# ATSAMV71J register map
Vendor: Microchip Technology; Series: SAMV71; File version: 0
CPU: CM7 r1p1, little endian, MPU, FPU, 3 interrupt priority bits
Registers are 32-bit, read-write, reset 0x0 unless marked. A register's access mark holds for its fields unless they carry their own. Offsets are from the block's base; [hi:lo] are bit positions.

## RSTC — Reset Controller
Base 0x400E1800; register names take the prefix RSTC_
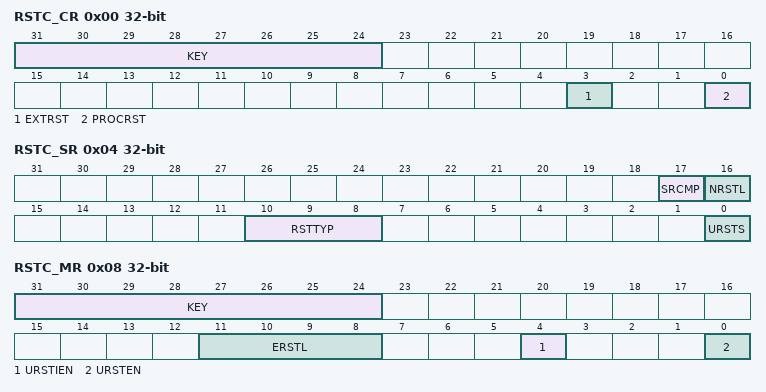
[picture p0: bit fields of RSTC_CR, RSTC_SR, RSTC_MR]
0x00 RSTC_CR wo — Control Register
  [31:24] KEY — System Reset Key
    165=PASSWD (Writing any other value in this field aborts the write operation.)
  [3] EXTRST — External Reset
  [0] PROCRST — Processor Reset
0x04 RSTC_SR ro — Status Register
  [17] SRCMP — Software Reset Command in Progress
  [16] NRSTL — NRST Pin Level
  [10:8] RSTTYP — Reset Type
    0=GENERAL_RST (First powerup reset); 1=BACKUP_RST (Return from Backup mode); 2=WDT_RST (Watchdog fault occurred); 3=SOFT_RST (Processor reset required by the software); 4=USER_RST (NRST pin detected low)
  [0] URSTS — User Reset Status
0x08 RSTC_MR — Mode Register
  [31:24] KEY — Write Access Password
    165=PASSWD (Writing any other value in this field aborts the write operation.Always reads as 0.)
  [11:8] ERSTL — External Reset Length
  [4] URSTIEN — User Reset Interrupt Enable
  [0] URSTEN — User Reset Enable

## RSWDT — Reinforced Safety Watchdog Timer
Base 0x400E1900; register names take the prefix RSWDT_
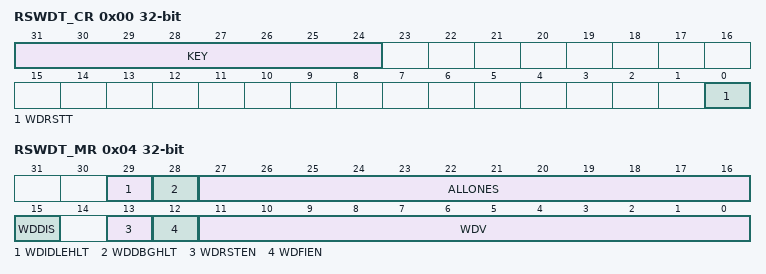
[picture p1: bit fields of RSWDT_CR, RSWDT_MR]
0x00 RSWDT_CR wo — Control Register
  [31:24] KEY — Password
    196=PASSWD (Writing any other value in this field aborts the write operation.)
  [0] WDRSTT — Watchdog Restart
0x04 RSWDT_MR — Mode Register
  [29] WDIDLEHLT — Watchdog Idle Halt
  [28] WDDBGHLT — Watchdog Debug Halt
  [27:16] ALLONES — Must Always Be Written with 0xFFF
  [15] WDDIS — Watchdog Disable
  [13] WDRSTEN — Watchdog Reset Enable
  [12] WDFIEN — Watchdog Fault Interrupt Enable
  [11:0] WDV — Watchdog Counter Value
0x08 RSWDT_SR ro — Status Register
  [0] WDUNF — Watchdog Underflow

## RTT — Real-time Timer
Base 0x400E1830; register names take the prefix RTT_
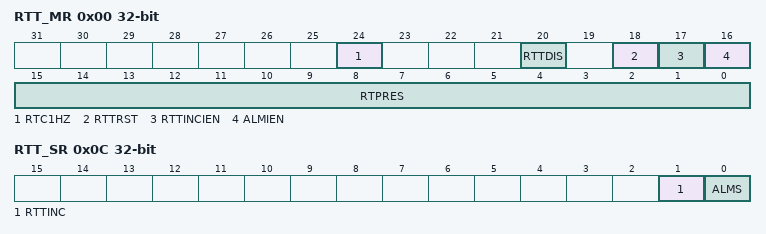
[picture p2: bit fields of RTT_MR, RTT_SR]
0x00 RTT_MR — Mode Register
  [24] RTC1HZ — Real-Time Clock 1Hz Clock Selection
  [20] RTTDIS — Real-time Timer Disable
  [18] RTTRST — Real-time Timer Restart
  [17] RTTINCIEN — Real-time Timer Increment Interrupt Enable
  [16] ALMIEN — Alarm Interrupt Enable
  [15:0] RTPRES — Real-time Timer Prescaler Value
0x04 RTT_AR — Alarm Register
  [31:0] ALMV — Alarm Value
0x08 RTT_VR ro — Value Register
  [31:0] CRTV — Current Real-time Value
0x0C RTT_SR ro — Status Register
  [1] RTTINC — Prescaler Roll-over Status (cleared on read)
  [0] ALMS — Real-time Alarm Status (cleared on read)

## TRNG — True Random Number Generator
Base 0x40070000; register names take the prefix TRNG_
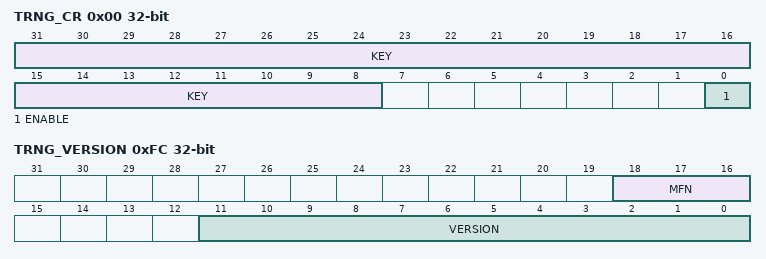
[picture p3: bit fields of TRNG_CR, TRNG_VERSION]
0x00 TRNG_CR wo — Control Register
  [31:8] KEY — Security Key
    0x524E47=PASSWD (Writing any other value in this field aborts the write operation.)
  [0] ENABLE — Enables the TRNG to Provide Random Values
0x10 TRNG_IER wo — Interrupt Enable Register
  [0] DATRDY — Data Ready Interrupt Enable
0x14 TRNG_IDR wo — Interrupt Disable Register
  [0] DATRDY — Data Ready Interrupt Disable
0x18 TRNG_IMR ro — Interrupt Mask Register
  [0] DATRDY — Data Ready Interrupt Mask
0x1C TRNG_ISR ro — Interrupt Status Register
  [0] DATRDY — Data Ready
0x50 TRNG_ODATA ro — Output Data Register
  [31:0] ODATA — Output Data
0xFC TRNG_VERSION ro — Version Register
  [18:16] MFN — Metal Fix Number
  [11:0] VERSION — Version of the Hardware Module

## UART0 — Universal Asynchronous Receiver Transmitter
Base 0x400E0800; register names take the prefix UART_
Same registers: UART1 0x400E0A00, UART2 0x400E1A00
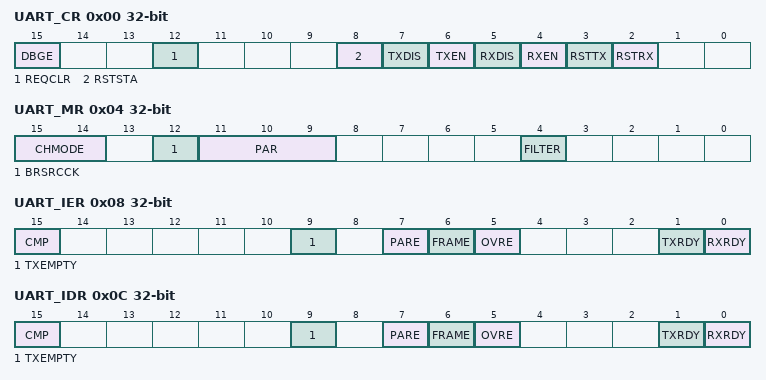
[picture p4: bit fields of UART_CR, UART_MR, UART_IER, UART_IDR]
0x00 UART_CR wo — Control Register
  [15] DBGE — Debug Enable
  [12] REQCLR — Request Clear
  [8] RSTSTA — Reset Status
  [7] TXDIS — Transmitter Disable
  [6] TXEN — Transmitter Enable
  [5] RXDIS — Receiver Disable
  [4] RXEN — Receiver Enable
  [3] RSTTX — Reset Transmitter
  [2] RSTRX — Reset Receiver
0x04 UART_MR — Mode Register
  [15:14] CHMODE — Channel Mode
    0=NORMAL (Normal mode); 1=AUTOMATIC (Automatic echo); 2=LOCAL_LOOPBACK; 3=REMOTE_LOOPBACK
  [12] BRSRCCK — Baud Rate Source Clock
    0=PERIPH_CLK (The baud rate is driven by the peripheral clock); 1=PMC_PCK (The baud rate is driven by a PMC-programmable clock PCK (see section Power Management Controller (PMC)).)
  [11:9] PAR — Parity Type
    0=EVEN (Even Parity); 1=ODD (Odd Parity); 2=SPACE (Space: parity forced to 0); 3=MARK (Mark: parity forced to 1); 4=NO (No parity)
  [4] FILTER — Receiver Digital Filter
    0=DISABLED (UART does not filter the receive line.); 1=ENABLED (UART filters the receive line using a three-sample filter (16x-bit clock) (2 over 3 majority).)
0x08 UART_IER wo — Interrupt Enable Register
  [15] CMP — Enable Comparison Interrupt
  [9] TXEMPTY — Enable TXEMPTY Interrupt
  [7] PARE — Enable Parity Error Interrupt
  [6] FRAME — Enable Framing Error Interrupt
  [5] OVRE — Enable Overrun Error Interrupt
  [1] TXRDY — Enable TXRDY Interrupt
  [0] RXRDY — Enable RXRDY Interrupt
0x0C UART_IDR wo — Interrupt Disable Register
  [15] CMP — Disable Comparison Interrupt
  [9] TXEMPTY — Disable TXEMPTY Interrupt
  [7] PARE — Disable Parity Error Interrupt
  [6] FRAME — Disable Framing Error Interrupt
  [5] OVRE — Disable Overrun Error Interrupt
  [1] TXRDY — Disable TXRDY Interrupt
  [0] RXRDY — Disable RXRDY Interrupt
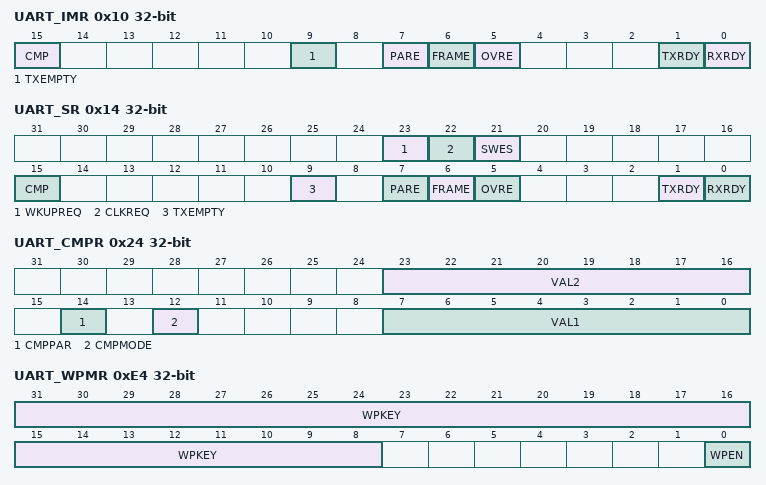
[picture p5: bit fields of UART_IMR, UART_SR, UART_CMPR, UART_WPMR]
0x10 UART_IMR ro — Interrupt Mask Register
  [15] CMP — Mask Comparison Interrupt
  [9] TXEMPTY — Mask TXEMPTY Interrupt
  [7] PARE — Mask Parity Error Interrupt
  [6] FRAME — Mask Framing Error Interrupt
  [5] OVRE — Mask Overrun Error Interrupt
  [1] TXRDY — Disable TXRDY Interrupt
  [0] RXRDY — Mask RXRDY Interrupt
0x14 UART_SR ro — Status Register
  [23] WKUPREQ — Wake-Up Request
  [22] CLKREQ — Clock Request
  [21] SWES — SleepWalking Enable Status
  [15] CMP — Comparison Match
  [9] TXEMPTY — Transmitter Empty
  [7] PARE — Parity Error
  [6] FRAME — Framing Error
  [5] OVRE — Overrun Error
  [1] TXRDY — Transmitter Ready
  [0] RXRDY — Receiver Ready
0x18 UART_RHR ro — Receive Holding Register
  [7:0] RXCHR — Received Character
0x1C UART_THR wo — Transmit Holding Register
  [7:0] TXCHR — Character to be Transmitted
0x20 UART_BRGR — Baud Rate Generator Register
  [15:0] CD — Clock Divisor
0x24 UART_CMPR — Comparison Register
  [23:16] VAL2 — Second Comparison Value for Received Character
  [14] CMPPAR — Compare Parity
  [12] CMPMODE — Comparison Mode
    0=FLAG_ONLY (Any character is received and comparison function drives CMP flag.); 1=START_CONDITION (Comparison condition must be met to start reception.)
  [7:0] VAL1 — First Comparison Value for Received Character
0xE4 UART_WPMR — Write Protection Mode Register
  [31:8] WPKEY — Write Protection Key
    0x554152=PASSWD (Writing any other value in this field aborts the write operation.Always reads as 0.)
  [0] WPEN — Write Protection Enable
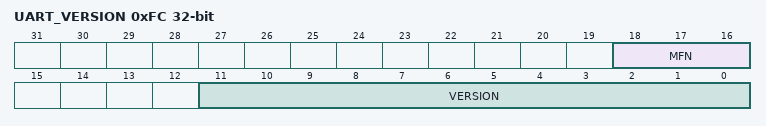
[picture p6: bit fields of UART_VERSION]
0xFC UART_VERSION ro — Version Register
  [18:16] MFN — Metal Fix Number
  [11:0] VERSION — Hardware Module Version

## Notices in the file
Copyright (c) 2017 Microchip Technology Inc.
SPDX-License-Identifier: Apache-2.0
Licensed under the Apache License, Version 2.0 (the "License");
you may not use this file except in compliance with the License.
You may obtain a copy of the License at
http://www.apache.org/licenses/LICENSE-2.0
Unless required by applicable law or agreed to in writing, software
distributed under the License is distributed on an "AS IS" BASIS,
WITHOUT WARRANTIES OR CONDITIONS OF ANY KIND, either express or implied.
See the License for the specific language governing permissions and
limitations under the License.
